# f28p551x_mem_cfg_regs register map
Vendor: Texas Instruments
Peripheral module from a debugger description file (folder C2000).
Address unit: 16 bits
Registers are 32-bit, read-write, no defined reset value unless marked. A register's access mark holds for its fields unless they carry their own. Offsets are as the file gives them; lines under a group give offsets from that group; [hi:lo] are bit positions; {n}, {i} and the like mark numbered series; 'fields as' and 'values as' point back to an identical list; <NAME> marks a mode.

## MEM_CFG_REGS — MEM CFG Registers
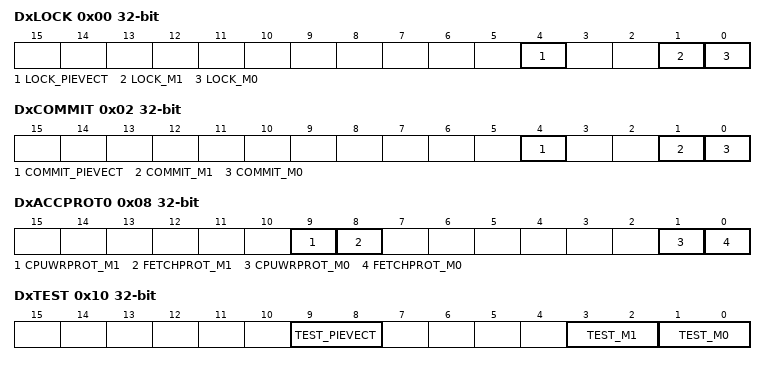
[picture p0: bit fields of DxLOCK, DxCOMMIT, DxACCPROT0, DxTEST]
0x00 DxLOCK — Dedicated RAM Config Lock Register
  [4] LOCK_PIEVECT — PIEVECT RAM Lock bits
  [1] LOCK_M1 — M1 RAM Lock bits
  [0] LOCK_M0 — M0 RAM Lock bits
0x02 DxCOMMIT — Dedicated RAM Config Lock Commit Register
  [4] COMMIT_PIEVECT — PIEVECT RAM Permanent Lock bits
  [1] COMMIT_M1 — M1 RAM Permanent Lock bits
  [0] COMMIT_M0 — M0 RAM Permanent Lock bits
0x08 DxACCPROT0 — Dedicated RAM Config Register
  [9] CPUWRPROT_M1 — CPU WR Protection For M1 RAM
  [8] FETCHPROT_M1 — Fetch Protection For M1 RAM
  [1] CPUWRPROT_M0 — CPU WR Protection For M0 RAM
  [0] FETCHPROT_M0 — Fetch Protection For M0 RAM
0x0A DxACCPROT1 — Dedicated RAM Config Register
  [1] CPUWRPROT_PIEVECT — CPU WR Protection For PIEVECT RAM
0x10 DxTEST — Dedicated RAM TEST Register
  [9:8] TEST_PIEVECT — Selects the different modes for PIEVECT RAM
  [3:2] TEST_M1 — Selects the different modes for M1 RAM
  [1:0] TEST_M0 — Selects the different modes for M0 RAM
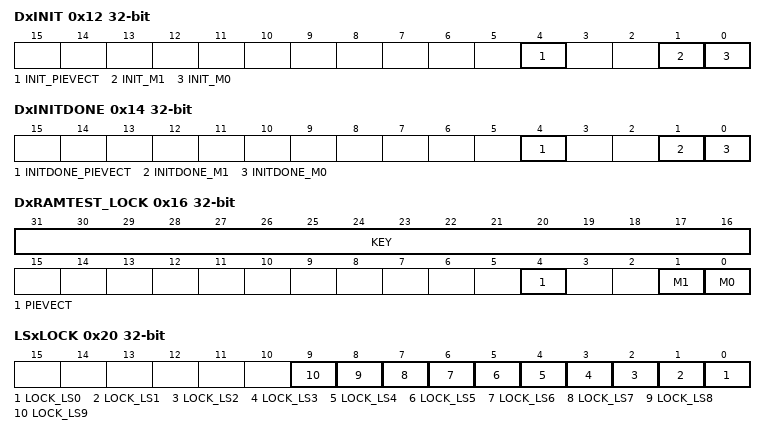
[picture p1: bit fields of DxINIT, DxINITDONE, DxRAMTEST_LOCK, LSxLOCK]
0x12 DxINIT — Dedicated RAM Init Register
  [4] INIT_PIEVECT — RAM Initialization control for PIEVECT RAM.
  [1] INIT_M1 — RAM Initialization control for M1 RAM.
  [0] INIT_M0 — RAM Initialization control for M0 RAM.
0x14 DxINITDONE ro — Dedicated RAM InitDone Status Register
  [4] INITDONE_PIEVECT — RAM Initialization status for PIEVECT RAM.
  [1] INITDONE_M1 — RAM Initialization status for M1 RAM.
  [0] INITDONE_M0 — RAM Initialization status for M0 RAM.
0x16 DxRAMTEST_LOCK — Lock register to Dx RAM TEST registers
  [31:16] KEY — Key for writing DxRAMTEST_LOCK
  [4] PIEVECT — DxTEST.TEST_PIEVECT LOCK
  [1] M1 — DxTEST.TEST_M1 LOCK
  [0] M0 — DxTEST.TEST_M0 LOCK
0x20 LSxLOCK — Local Shared RAM Config Lock Register
  [n] LOCK_LS{n} (n=0..9) — LS{n} RAM Lock bits
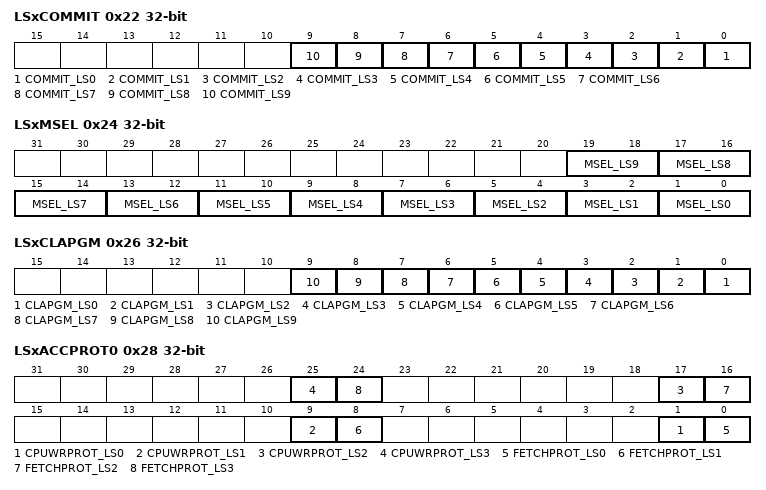
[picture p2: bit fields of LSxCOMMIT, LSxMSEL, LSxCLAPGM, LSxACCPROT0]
0x22 LSxCOMMIT — Local Shared RAM Config Lock Commit Register
  [n] COMMIT_LS{n} (n=0..9) — LS{n} RAM Permanent Lock bits
0x24 LSxMSEL — Local Shared RAM Controller Sel Register
  [2n+1:2n] MSEL_LS{n} (n=0..9) — Controller Select for LS{n} RAM
0x26 LSxCLAPGM — Local Shared RAM Prog/Exe control Register
  [n] CLAPGM_LS{n} (n=0..9) — Selects LS{n} RAM as program vs data memory for CLA
0x28 LSxACCPROT0 — Local Shared RAM Config Register 0
  [8n+1] CPUWRPROT_LS{n} (n=0..3) — CPU WR Protection For LS{n} RAM
  [8n] FETCHPROT_LS{n} (n=0..3) — Fetch Protection For LS{n} RAM
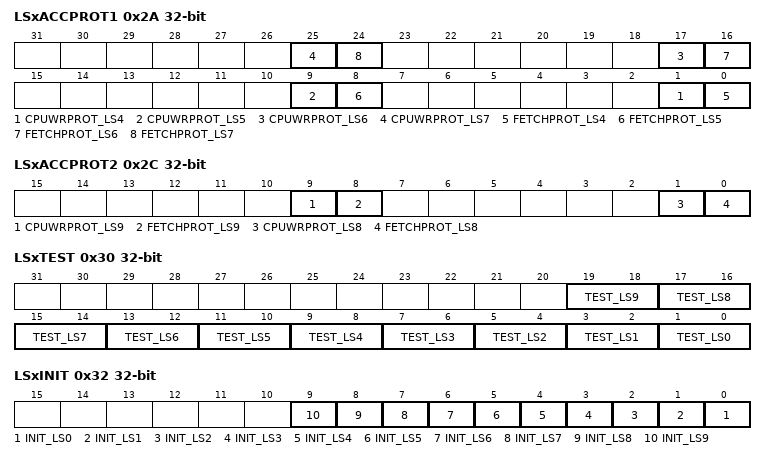
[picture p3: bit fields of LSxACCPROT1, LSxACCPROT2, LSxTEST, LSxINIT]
0x2A LSxACCPROT1 — Local Shared RAM Config Register 1
  [8n-31] CPUWRPROT_LS{n} (n=4..7) — CPU WR Protection For LS{n} RAM
  [8n-32] FETCHPROT_LS{n} (n=4..7) — Fetch Protection For LS{n} RAM
0x2C LSxACCPROT2 — Local Shared RAM Config Register 2
  [9] CPUWRPROT_LS9 — CPU WR Protection For LS9 RAM
  [8] FETCHPROT_LS9 — Fetch Protection For LS9 RAM
  [1] CPUWRPROT_LS8 — CPU WR Protection For LS8 RAM
  [0] FETCHPROT_LS8 — Fetch Protection For LS8 RAM
0x30 LSxTEST — Local Shared RAM TEST Register
  [2n+1:2n] TEST_LS{n} (n=0..9) — Selects the different modes for LS{n} RAM
0x32 LSxINIT — Local Shared RAM Init Register
  [n] INIT_LS{n} (n=0..9) — RAM Initialization control for LS{n} RAM.
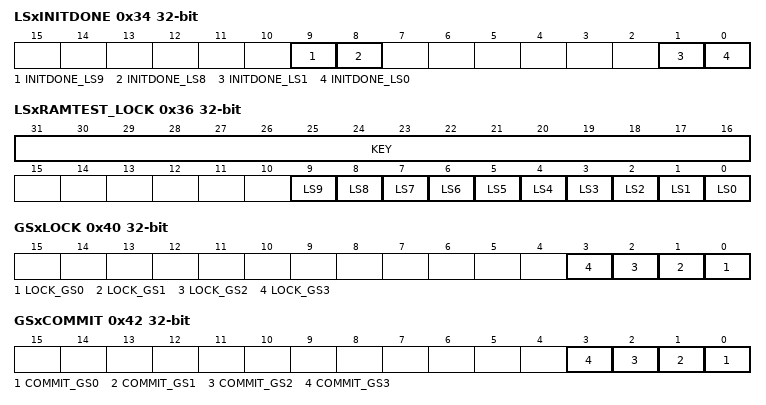
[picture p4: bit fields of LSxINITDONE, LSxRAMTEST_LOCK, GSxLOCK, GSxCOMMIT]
0x34 LSxINITDONE ro — Local Shared RAM InitDone Status Register
  [9] INITDONE_LS9 — RAM Initialization status for LS9 RAM.
  [8] INITDONE_LS8 — RAM Initialization status for LS8 RAM.
  [1] INITDONE_LS1 — RAM Initialization status for LS1 RAM.
  [0] INITDONE_LS0 — RAM Initialization status for LS0 RAM.
0x36 LSxRAMTEST_LOCK — Lock register to LSx RAM TEST registers
  [31:16] KEY — KEY to enable write to lock
  [n] LS{n} (n=0..9) — LSxTEST.TEST_LS{n} LOCK
0x40 GSxLOCK — Global Shared RAM Config Lock Register
  [n] LOCK_GS{n} (n=0..3) — GS{n} RAM Lock bits
0x42 GSxCOMMIT — Global Shared RAM Config Lock Commit Register
  [n] COMMIT_GS{n} (n=0..3) — GS{n} RAM Permanent Lock bits
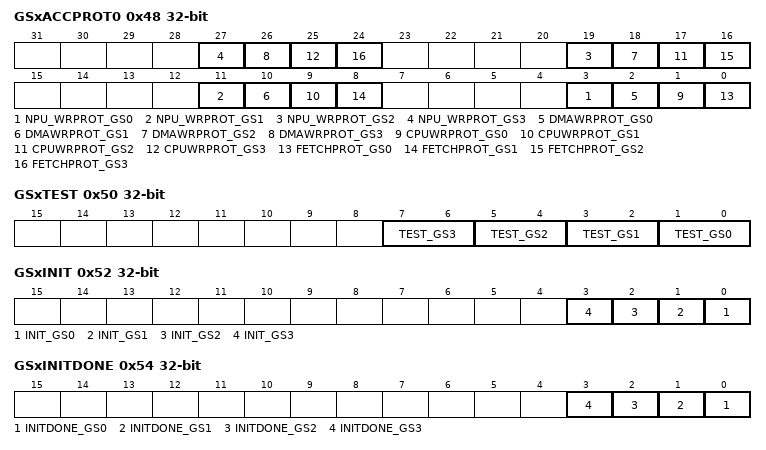
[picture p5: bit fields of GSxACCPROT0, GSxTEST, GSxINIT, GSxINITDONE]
0x48 GSxACCPROT0 — Global Shared RAM Config Register 0
  [8n+3] NPU_WRPROT_GS{n} (n=0..3) — NPU WR Protection For GS{n} RAM
  [8n+2] DMAWRPROT_GS{n} (n=0..3) — DMA WR Protection For GS{n} RAM
  [8n+1] CPUWRPROT_GS{n} (n=0..3) — CPU WR Protection For GS{n} RAM
  [8n] FETCHPROT_GS{n} (n=0..3) — Fetch Protection For GS{n} RAM
0x50 GSxTEST — Global Shared RAM TEST Register
  [2n+1:2n] TEST_GS{n} (n=0..3) — Selects the different modes for GS{n} RAM
0x52 GSxINIT — Global Shared RAM Init Register
  [n] INIT_GS{n} (n=0..3) — RAM Initialization control for GS{n} RAM.
0x54 GSxINITDONE ro — Global Shared RAM InitDone Status Register
  [n] INITDONE_GS{n} (n=0..3) — RAM Initialization status for GS{n} RAM.
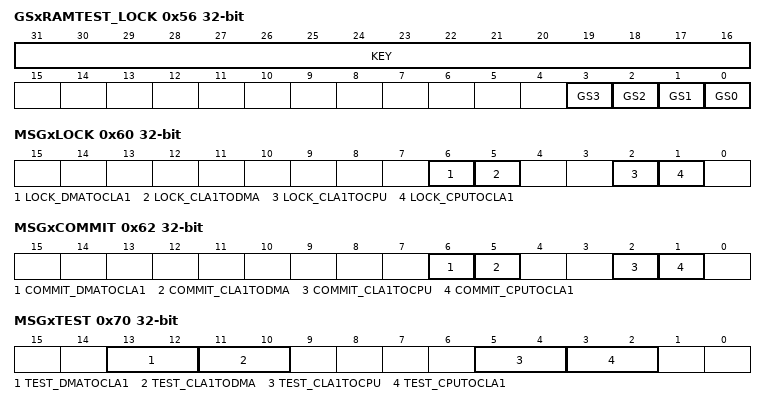
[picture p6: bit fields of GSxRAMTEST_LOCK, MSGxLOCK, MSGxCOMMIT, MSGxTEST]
0x56 GSxRAMTEST_LOCK — Lock register to GSx RAM TEST registers
  [31:16] KEY — KEY to enable write to lock
  [n] GS{n} (n=0..3) — GSxTEST.TEST_GS{n} LOCK
0x60 MSGxLOCK — Message RAM Config Lock Register
  [6] LOCK_DMATOCLA1 — DMATOCLA1 RAM control fields lock bit
  [5] LOCK_CLA1TODMA — CLA1TODMA RAM control fields lock bit
  [2] LOCK_CLA1TOCPU — CLA1TOCPU RAM Lock bits
  [1] LOCK_CPUTOCLA1 — CPUTOCLA1 RAM Lock bits
0x62 MSGxCOMMIT — Message RAM Config Lock Commit Register
  [6] COMMIT_DMATOCLA1 — DMATOCLA1 RAM control fields COMMIT bit
  [5] COMMIT_CLA1TODMA — CLA1TODMA RAM control fields COMMIT bit
  [2] COMMIT_CLA1TOCPU — CLA1TOCPU RAM control fields COMMIT bit
  [1] COMMIT_CPUTOCLA1 — CPUTOCLA1 RAM control fields COMMIT bit
0x70 MSGxTEST — Message RAM TEST Register
  [13:12] TEST_DMATOCLA1 — DMA to CLA1 MSG RAM Mode Select
  [11:10] TEST_CLA1TODMA — CLA1 to DMA MSG RAM Mode Select
  [5:4] TEST_CLA1TOCPU — CLA1 to CPU MSG RAM Mode Select
  [3:2] TEST_CPUTOCLA1 — CPU to CLA1 MSG RAM Mode Select
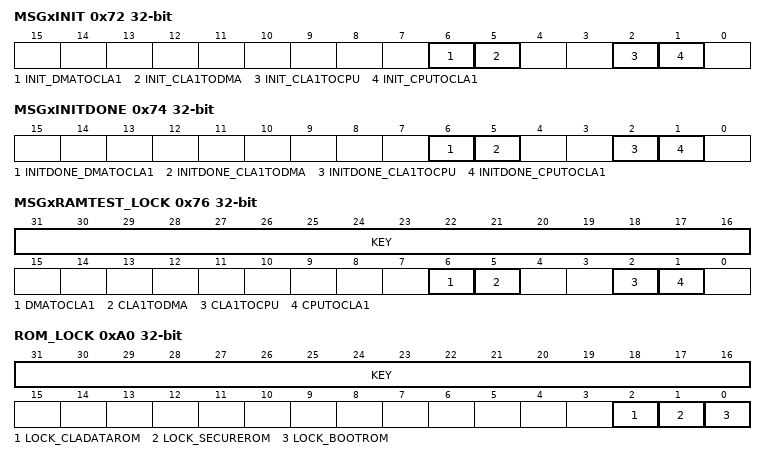
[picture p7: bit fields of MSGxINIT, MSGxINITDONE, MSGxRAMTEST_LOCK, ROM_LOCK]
0x72 MSGxINIT — Message RAM Init Register
  [6] INIT_DMATOCLA1 — Initialization control for DMA to CLA1 MSG RAM
  [5] INIT_CLA1TODMA — Initialization control for CLA1 to DMA MSG RAM
  [2] INIT_CLA1TOCPU — Initialization control for CLA1TOCPU MSG RAM
  [1] INIT_CPUTOCLA1 — Initialization control for CPUTOCLA1 MSG RAM
0x74 MSGxINITDONE ro — Message RAM InitDone Status Register
  [6] INITDONE_DMATOCLA1 — Initialization status for DMA to CLA1 MSG RAM
  [5] INITDONE_CLA1TODMA — Initialization status for CLA1 to DMA MSG RAM
  [2] INITDONE_CLA1TOCPU — Initialization status for CLA1 to CPU MSG RAM
  [1] INITDONE_CPUTOCLA1 — Initialization status for CPU to CLA1 MSG RAM
0x76 MSGxRAMTEST_LOCK — Lock register for MSGx RAM TEST Register
  [31:16] KEY — KEY to enable write to lock
  [6] DMATOCLA1 — MSGxRAMTEST_LOCK.DMATOCLA1Lock Configuration
  [5] CLA1TODMA — MSGxRAMTEST_LOCK.CLA1TODMALock Configuration
  [2] CLA1TOCPU — MSGxRAMTEST_LOCK.CLA1TOCPULock Configuration
  [1] CPUTOCLA1 — MSGxRAMTEST_LOCK.CPUTOCLA1Lock Configuration
0xA0 ROM_LOCK — ROM Config Lock Register
  [31:16] KEY — Key for writing ROM LOCK
  [2] LOCK_CLADATAROM — CLADATAROM Lock bits
  [1] LOCK_SECUREROM — SECUREROM Lock bits
  [0] LOCK_BOOTROM — BOOTROM Lock bits
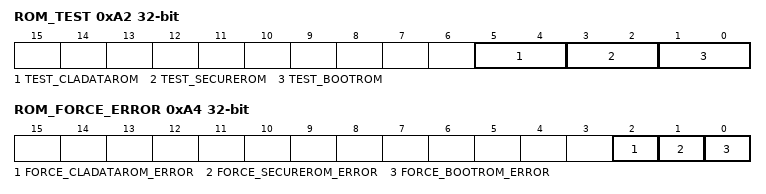
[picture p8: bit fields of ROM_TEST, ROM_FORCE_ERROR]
0xA2 ROM_TEST
  [5:4] TEST_CLADATAROM — Selects the different modes for CLADATAROM
  [3:2] TEST_SECUREROM — Selects the different modes for SECUREROM
  [1:0] TEST_BOOTROM — Selects the different modes for BOOTROM
0xA4 ROM_FORCE_ERROR
  [2] FORCE_CLADATAROM_ERROR — Force CLADATAROM Parity Error
  [1] FORCE_SECUREROM_ERROR — Force SECUREROM Parity Error
  [0] FORCE_BOOTROM_ERROR — Force Bootrom Parity Error
